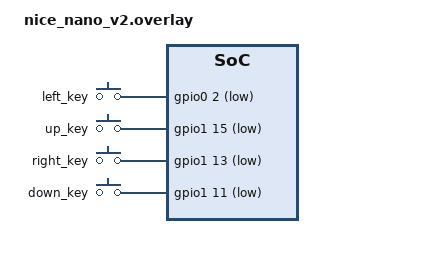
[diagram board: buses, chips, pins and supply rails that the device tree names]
/ {
    // --- 既存の kscan0 はそのまま ---

    // スティック用の4方向キーを追加する
    gpio_keys {
        compatible = "zmk,gpio-keys";
        label = "StickKeys";

        left_key: left_key {
            gpios = <&gpio0 2 (GPIO_ACTIVE_LOW | GPIO_PULL_UP)>;
            zmk,behavior = <&mo 1>;
        };

        up_key: up_key {
            gpios = <&gpio1 15 (GPIO_ACTIVE_LOW | GPIO_PULL_UP)>;
            zmk,behavior = <&mo 2>;
        };

        right_key: right_key {
            gpios = <&gpio1 13 (GPIO_ACTIVE_LOW | GPIO_PULL_UP)>;
            zmk,behavior = <&mo 3>;
        };

        down_key: down_key {
            gpios = <&gpio1 11 (GPIO_ACTIVE_LOW | GPIO_PULL_UP)>;
            zmk,behavior = <&mo 4>;
        };
    };
};
